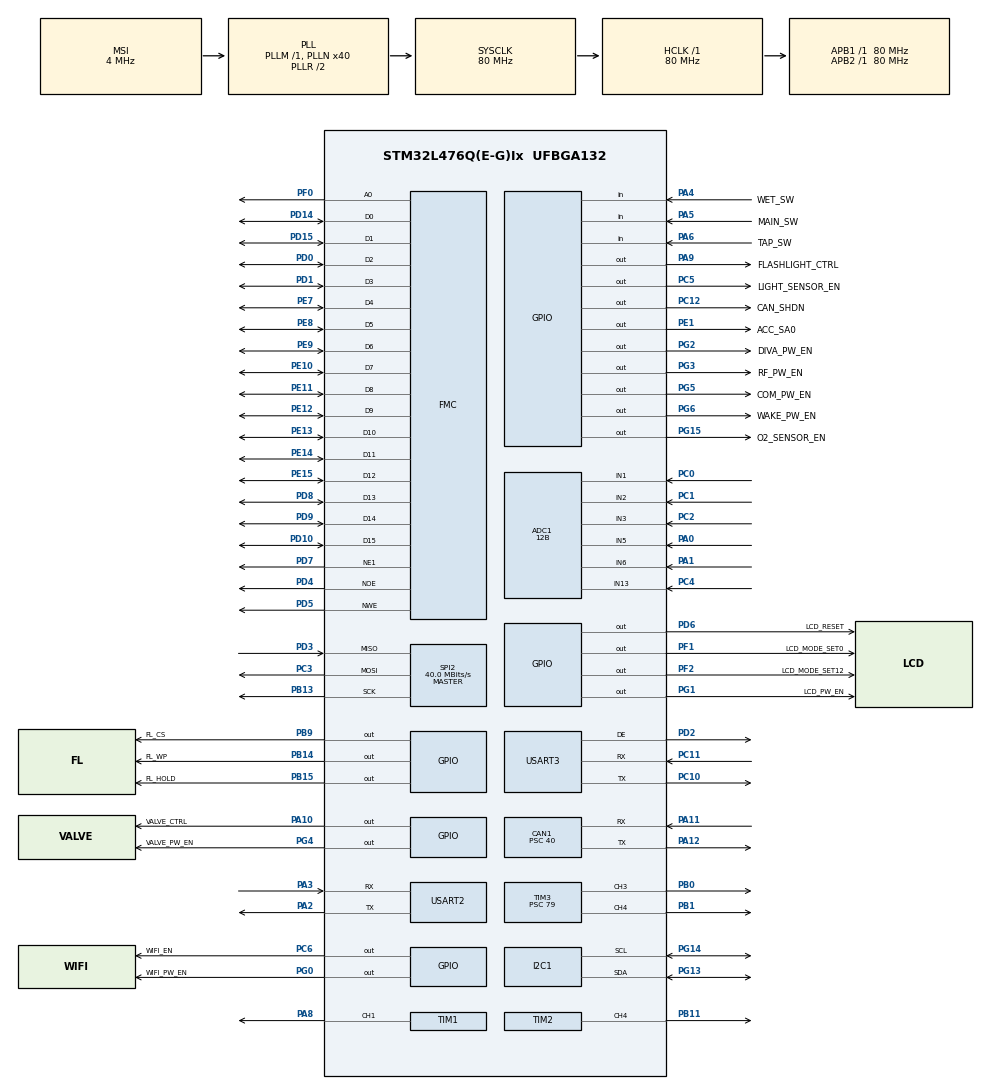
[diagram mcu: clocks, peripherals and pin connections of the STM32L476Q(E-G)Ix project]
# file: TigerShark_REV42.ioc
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ADC1.Channel-0\#ChannelRegularConversion=ADC_CHANNEL_1
ADC1.Channel-1\#ChannelRegularConversion=ADC_CHANNEL_2
ADC1.Channel-2\#ChannelRegularConversion=ADC_CHANNEL_3
ADC1.Channel-3\#ChannelRegularConversion=ADC_CHANNEL_5
ADC1.Channel-4\#ChannelRegularConversion=ADC_CHANNEL_6
ADC1.Channel-5\#ChannelRegularConversion=ADC_CHANNEL_13
ADC1.Channel-6\#ChannelRegularConversion=ADC_CHANNEL_VREFINT
ADC1.ClockPrescaler=ADC_CLOCK_ASYNC_DIV1
ADC1.ContinuousConvMode=DISABLE
ADC1.DMAContinuousRequests=ENABLE
ADC1.DataAlign=ADC_DATAALIGN_RIGHT
ADC1.EOCSelection=ADC_EOC_SINGLE_CONV
ADC1.ExternalTrigConv=ADC_EXTERNALTRIG_T4_TRGO
ADC1.NbrOfConversion=7
ADC1.NbrOfConversionFlag=1
ADC1.OffsetNumber-0\#ChannelRegularConversion=ADC_OFFSET_NONE
ADC1.OffsetNumber-1\#ChannelRegularConversion=ADC_OFFSET_NONE
ADC1.OffsetNumber-2\#ChannelRegularConversion=ADC_OFFSET_NONE
ADC1.OffsetNumber-3\#ChannelRegularConversion=ADC_OFFSET_NONE
ADC1.OffsetNumber-4\#ChannelRegularConversion=ADC_OFFSET_NONE
ADC1.OffsetNumber-5\#ChannelRegularConversion=ADC_OFFSET_NONE
ADC1.OffsetNumber-6\#ChannelRegularConversion=ADC_OFFSET_NONE
ADC1.OversamplingMode=DISABLE
ADC1.Rank-0\#ChannelRegularConversion=1
ADC1.Rank-1\#ChannelRegularConversion=2
ADC1.Rank-2\#ChannelRegularConversion=3
ADC1.Rank-3\#ChannelRegularConversion=4
ADC1.Rank-4\#ChannelRegularConversion=5
ADC1.Rank-5\#ChannelRegularConversion=6
ADC1.Rank-6\#ChannelRegularConversion=7
ADC1.Resolution=ADC_RESOLUTION_12B
ADC1.SamplingTime-0\#ChannelRegularConversion=ADC_SAMPLETIME_92CYCLES_5
ADC1.SamplingTime-1\#ChannelRegularConversion=ADC_SAMPLETIME_92CYCLES_5
ADC1.SamplingTime-2\#ChannelRegularConversion=ADC_SAMPLETIME_92CYCLES_5
ADC1.SamplingTime-3\#ChannelRegularConversion=ADC_SAMPLETIME_92CYCLES_5
ADC1.SamplingTime-4\#ChannelRegularConversion=ADC_SAMPLETIME_92CYCLES_5
ADC1.SamplingTime-5\#ChannelRegularConversion=ADC_SAMPLETIME_92CYCLES_5
ADC1.SamplingTime-6\#ChannelRegularConversion=ADC_SAMPLETIME_92CYCLES_5
ADC1.master=1
CAN1.BS1=CAN_BS1_2TQ
CAN1.BS2=CAN_BS2_3TQ
CAN1.CalculateBaudRate=333333
CAN1.CalculateTimeBit=3000.00
CAN1.CalculateTimeQuantum=500.0
CAN1.Prescaler=40
Dma.ADC1.0.Direction=DMA_PERIPH_TO_MEMORY
Dma.ADC1.0.Instance=DMA1_Channel1
Dma.ADC1.0.MemDataAlignment=DMA_MDATAALIGN_HALFWORD
Dma.ADC1.0.MemInc=DMA_MINC_ENABLE
Dma.ADC1.0.Mode=DMA_CIRCULAR
Dma.ADC1.0.PeriphDataAlignment=DMA_PDATAALIGN_HALFWORD
Dma.ADC1.0.PeriphInc=DMA_PINC_DISABLE
Dma.ADC1.0.Priority=DMA_PRIORITY_LOW
Dma.Request0=ADC1
FMC.AddressSetupTime1=0
FMC.BusTurnAroundDuration1=3
FMC.DataSetupTime1=1
I2C1.Speed=100
I2C1.Timing=0x10909CEC
Mcu.Family=STM32L4
Mcu.Name=STM32L476Q(E-G)Ix
Mcu.Package=UFBGA132
NVIC.ADC1_2_IRQn=true\:0\:0\:false\:false\:true\:true\:true
NVIC.CAN1_RX0_IRQn=true\:0\:0\:false\:false\:true\:true\:true
NVIC.DMA1_Channel1_IRQn=true\:0\:0\:false\:false\:true\:false\:true
NVIC.PriorityGroup=NVIC_PRIORITYGROUP_4
PA0.Signal=ADCx_IN5
PA1.Signal=ADCx_IN6
PA10.GPIO_Label=VALVE_CTRL
PA10.GPIO_ModeDefaultOutputPP=GPIO_MODE_OUTPUT_PP
PA10.GPIO_PuPd=GPIO_PULLUP
PA10.GPIO_Speed=GPIO_SPEED_FREQ_VERY_HIGH
PA10.PinState=GPIO_PIN_SET
PA10.Signal=GPIO_Output
PA11.Mode=CAN_Activate
PA11.Signal=CAN1_RX
PA12.Mode=CAN_Activate
PA12.Signal=CAN1_TX
PA13\ (JTMS-SWDIO).Mode=Serial_Wire
PA13\ (JTMS-SWDIO).Signal=SYS_JTMS-SWDIO
PA14\ (JTCK-SWCLK).Mode=Serial_Wire
PA14\ (JTCK-SWCLK).Signal=SYS_JTCK-SWCLK
PA2.Mode=Asynchronous
PA2.Signal=USART2_TX
PA3.Mode=Asynchronous
PA3.Signal=USART2_RX
PA4.GPIO_Label=WET_SW
PA4.GPIO_PuPd=GPIO_PULLUP
PA4.Signal=GPIO_Input
PA5.GPIO_Label=MAIN_SW
PA5.GPIO_PuPd=GPIO_NOPULL
PA5.Signal=GPIO_Input
PA6.GPIO_Label=TAP_SW
PA6.GPIO_PuPd=GPIO_NOPULL
PA6.Signal=GPIO_Input
PA8.Signal=S_TIM1_CH1
PA9.GPIO_Label=FLASHLIGHT_CTRL
PA9.Signal=GPIO_Output
PB0.Signal=S_TIM3_CH3
PB1.Signal=S_TIM3_CH4
PB11.Signal=S_TIM2_CH4
PB13.Mode=Full_Duplex_Master
PB13.Signal=SPI2_SCK
PB14.GPIO_Label=FL_WP
PB14.GPIO_ModeDefaultOutputPP=GPIO_MODE_OUTPUT_PP
PB14.GPIO_PuPd=GPIO_PULLUP
PB14.GPIO_Speed=GPIO_SPEED_FREQ_LOW
PB14.PinState=GPIO_PIN_SET
PB14.Signal=GPIO_Output
PB15.GPIO_Label=FL_HOLD
PB15.GPIO_ModeDefaultOutputPP=GPIO_MODE_OUTPUT_PP
PB15.GPIO_PuPd=GPIO_PULLUP
PB15.PinState=GPIO_PIN_SET
PB15.Signal=GPIO_Output
PB9.GPIO_Label=FL_CS
PB9.GPIO_ModeDefaultOutputPP=GPIO_MODE_OUTPUT_PP
PB9.GPIO_PuPd=GPIO_PULLUP
PB9.GPIO_Speed=GPIO_SPEED_FREQ_LOW
PB9.PinState=GPIO_PIN_SET
PB9.Signal=GPIO_Output
PC0.Signal=ADCx_IN1
PC1.Signal=ADCx_IN2
PC10.Mode=Asynchronous
PC10.Signal=USART3_TX
PC11.Mode=Asynchronous
PC11.Signal=USART3_RX
PC12.GPIO_Label=CAN_SHDN
PC12.GPIO_ModeDefaultOutputPP=GPIO_MODE_OUTPUT_PP
PC12.GPIO_PuPd=GPIO_PULLUP
PC12.Signal=GPIO_Output
PC14-OSC32_IN\ (PC14).Mode=LSE-External-Oscillator
PC14-OSC32_IN\ (PC14).Signal=RCC_OSC32_IN
PC15-OSC32_OUT\ (PC15).Mode=LSE-External-Oscillator
PC15-OSC32_OUT\ (PC15).Signal=RCC_OSC32_OUT
PC2.Signal=ADCx_IN3
PC3.Mode=Full_Duplex_Master
PC3.Signal=SPI2_MOSI
PC4.Signal=ADCx_IN13
PC5.GPIO_Label=LIGHT_SENSOR_EN
PC5.GPIO_PuPd=GPIO_PULLUP
PC5.Signal=GPIO_Output
PC6.GPIO_Label=WIFI_EN
PC6.GPIO_ModeDefaultOutputPP=GPIO_MODE_OUTPUT_PP
PC6.GPIO_PuPd=GPIO_PULLUP
PC6.Signal=GPIO_Output
PD0.Signal=FMC_D2_DA2
PD1.Signal=FMC_D3_DA3
PD10.Signal=FMC_D15_DA15
PD14.Signal=FMC_D0_DA0
PD15.Signal=FMC_D1_DA1
PD2.Mode=Hardware Flow Control (RS485)
PD2.Signal=USART3_DE
PD3.Mode=Full_Duplex_Master
PD3.Signal=SPI2_MISO
PD4.Signal=FMC_NOE
PD5.Signal=FMC_NWE
PD6.GPIO_Label=LCD_RESET
PD6.GPIO_PuPd=GPIO_PULLUP
PD6.PinState=GPIO_PIN_SET
PD6.Signal=GPIO_Output
PD7.Mode=NorPsramChipSelect1_1
PD7.Signal=FMC_NE1
PD8.Signal=FMC_D13_DA13
PD9.Signal=FMC_D14_DA14
PE1.GPIO_Label=ACC_SA0
PE1.GPIO_PuPd=GPIO_PULLUP
PE1.Signal=GPIO_Output
PE10.Signal=FMC_D7_DA7
PE11.Signal=FMC_D8_DA8
PE12.Signal=FMC_D9_DA9
PE13.Signal=FMC_D10_DA10
PE14.Signal=FMC_D11_DA11
PE15.Signal=FMC_D12_DA12
PE7.Signal=FMC_D4_DA4
PE8.Signal=FMC_D5_DA5
PE9.Signal=FMC_D6_DA6
PF0.Signal=FMC_A0
PF1.GPIO_Label=LCD_MODE_SET0
PF1.GPIO_ModeDefaultOutputPP=GPIO_MODE_OUTPUT_PP
PF1.GPIO_PuPd=GPIO_PULLUP
PF1.PinState=GPIO_PIN_SET
PF1.Signal=GPIO_Output
PF2.GPIO_Label=LCD_MODE_SET12
PF2.GPIO_PuPd=GPIO_PULLDOWN
PF2.Signal=GPIO_Output
PG0.GPIO_Label=WIFI_PW_EN
PG0.Signal=GPIO_Output
PG1.GPIO_Label=LCD_PW_EN
PG1.Signal=GPIO_Output
PG13.Mode=I2C
PG13.Signal=I2C1_SDA
PG14.Mode=I2C
PG14.Signal=I2C1_SCL
PG15.GPIO_Label=O2_SENSOR_EN
PG15.Signal=GPIO_Output
PG2.GPIO_Label=DIVA_PW_EN
PG2.Signal=GPIO_Output
PG3.GPIO_Label=RF_PW_EN
PG3.Signal=GPIO_Output
PG4.GPIO_Label=VALVE_PW_EN
PG4.Signal=GPIO_Output
PG5.GPIO_Label=COM_PW_EN
PG5.Signal=GPIO_Output
PG6.GPIO_Label=WAKE_PW_EN
PG6.Signal=GPIO_Output
PH0-OSC_IN\ (PH0).Mode=HSE-External-Oscillator
PH0-OSC_IN\ (PH0).Signal=RCC_OSC_IN
PH1-OSC_OUT\ (PH1).Mode=HSE-External-Oscillator
PH1-OSC_OUT\ (PH1).Signal=RCC_OSC_OUT
ProjectManager.HeapSize=0x400
ProjectManager.StackSize=0x1024
ProjectManager.TargetToolchain=EWARM V8.32
RCC.ADCFreq_Value=32000000
RCC.AHBFreq_Value=80000000
RCC.APB1Freq_Value=80000000
RCC.APB1TimFreq_Value=80000000
RCC.APB2Freq_Value=80000000
RCC.APB2TimFreq_Value=80000000
RCC.CortexFreq_Value=80000000
RCC.HCLKFreq_Value=80000000
RCC.HSE_VALUE=8000000
RCC.HSI_VALUE=16000000
RCC.MSI_VALUE=4000000
RCC.PLLN=40
RCC.PLLSAI1N=16
RCC.SYSCLKFreq_VALUE=80000000
RCC.SYSCLKSource=RCC_SYSCLKSOURCE_PLLCLK
RCC.USBFreq_Value=32000000
RCC.VCOOutputFreq_Value=160000000
RTC.Date=16
RTC.Hours=15
RTC.Minutes=24
RTC.Month=RTC_MONTH_MAY
RTC.Year=22
SH.ADCx_IN1.0=ADC1_IN1,IN1-Single-Ended
SH.ADCx_IN13.0=ADC1_IN13,IN13-Single-Ended
SH.ADCx_IN2.0=ADC1_IN2,IN2-Single-Ended
SH.ADCx_IN3.0=ADC1_IN3,IN3-Single-Ended
SH.ADCx_IN5.0=ADC1_IN5,IN5-Single-Ended
SH.ADCx_IN6.0=ADC1_IN6,IN6-Single-Ended
SH.FMC_A0.0=FMC_A0,A0_1
SH.FMC_D0_DA0.0=FMC_D0,16b-d1
SH.FMC_D10_DA10.0=FMC_D10,16b-d1
SH.FMC_D11_DA11.0=FMC_D11,16b-d1
SH.FMC_D12_DA12.0=FMC_D12,16b-d1
SH.FMC_D13_DA13.0=FMC_D13,16b-d1
SH.FMC_D14_DA14.0=FMC_D14,16b-d1
SH.FMC_D15_DA15.0=FMC_D15,16b-d1
SH.FMC_D1_DA1.0=FMC_D1,16b-d1
SH.FMC_D2_DA2.0=FMC_D2,16b-d1
SH.FMC_D3_DA3.0=FMC_D3,16b-d1
SH.FMC_D4_DA4.0=FMC_D4,16b-d1
SH.FMC_D5_DA5.0=FMC_D5,16b-d1
SH.FMC_D6_DA6.0=FMC_D6,16b-d1
SH.FMC_D7_DA7.0=FMC_D7,16b-d1
SH.FMC_D8_DA8.0=FMC_D8,16b-d1
SH.FMC_D9_DA9.0=FMC_D9,16b-d1
SH.FMC_NOE.0=FMC_NOE,Lcd1
SH.FMC_NWE.0=FMC_NWE,Lcd1
SH.S_TIM1_CH1.0=TIM1_CH1,PWM Generation1 CH1
SH.S_TIM2_CH4.0=TIM2_CH4,PWM Generation4 CH4
SH.S_TIM3_CH3.0=TIM3_CH3,PWM Generation3 CH3
SH.S_TIM3_CH4.0=TIM3_CH4,PWM Generation4 CH4
SPI2.CalculateBaudRate=40.0 MBits/s
SPI2.DataSize=SPI_DATASIZE_8BIT
SPI2.Direction=SPI_DIRECTION_2LINES
SPI2.Mode=SPI_MODE_MASTER
SPI2.VirtualType=VM_MASTER
TIM1.Channel-PWM\ Generation1\ CH1=TIM_CHANNEL_1
TIM1.Period=499
TIM1.Prescaler=79
TIM1.Pulse-PWM\ Generation1\ CH1=100
TIM2.Channel-PWM\ Generation4\ CH4=TIM_CHANNEL_4
TIM2.OCPolarity_4=TIM_OCPOLARITY_HIGH
TIM2.Period=1000
TIM2.Prescaler=79
TIM3.Channel-PWM\ Generation3\ CH3=TIM_CHANNEL_3
TIM3.Channel-PWM\ Generation4\ CH4=TIM_CHANNEL_4
TIM3.OCMode_PWM-PWM\ Generation4\ CH4=TIM_OCMODE_PWM1
TIM3.OCPolarity_3=TIM_OCPOLARITY_HIGH
TIM3.OCPolarity_4=TIM_OCPOLARITY_HIGH
TIM3.Period=1000
TIM3.Prescaler=79
TIM3.Pulse-PWM\ Generation3\ CH3=0
TIM3.Pulse-PWM\ Generation4\ CH4=0
TIM4.Channel-Output\ Compare1\ No\ Output=TIM_CHANNEL_1
TIM4.Period=625
TIM4.Prescaler=79
TIM4.TIM_MasterOutputTrigger=TIM_TRGO_UPDATE
USART2.VirtualMode-Asynchronous=VM_ASYNC
USART3.VirtualMode-Asynchronous=VM_ASYNC
USART3.VirtualMode-Hardware\ Flow\ Control\ (RS485)=VM_ASYNC
VP_ADC1_Vref_Input.Mode=IN-Vrefint
VP_RTC_VS_RTC_Activate.Mode=RTC_Enabled
VP_RTC_VS_RTC_Calendar.Mode=RTC_Calendar
VP_TIM3_VS_ClockSourceINT.Mode=Internal
VP_TIM4_VS_no_output1.Mode=Output Compare1 No Output
board=custom

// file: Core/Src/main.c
/* USER CODE BEGIN Header */
/**
******************************************************************************
* @file           : main.c
* @brief          : Main program body
******************************************************************************
* @attention
*
* <h2><center>&copy; Copyright (c) 2022 STMicroelectronics.
* All rights reserved.</center></h2>
*
* This software component is licensed by ST under BSD 3-Clause license,
* the "License"; You may not use this file except in compliance with the
* License. You may obtain a copy of the License at:
*                        opensource.org/licenses/BSD-3-Clause
*
******************************************************************************
*/
/* USER CODE END Header */
#include "main.h"
#include "adc.h"
#include "can.h"
#include "dma.h"
#include "i2c.h"
#include "rtc.h"
#include "spi.h"
#include "tim.h"
#include "usart.h"
#include "gpio.h"
#include "fmc.h"

/* USER CODE BEGIN Includes */
#include "adc_process.h"
#include "ms5837.h"
#include "lvgl.h"
#include "lv_port_disp_template.h"
#include "main_process.h"
#include "ui_main.h"
#include "ui_menu.h"
#include "ui_dialog.h"
#include "ui_diagnotics.h"
#include "ui_splash.h"
#include "spi_ffs.h"
#include "power_management.h"
#include "flash_process.h"
#include "button_process.h"
#include "diva_process.h"
#include "compass.h"
#include "DFRobot_BMX160.h"
#include "veml7700.h"
#include "fn3161h.h"
// #include "lv_theme_default.h"
/* USER CODE END Includes */

/* USER CODE BEGIN PD */
#define FW_VERSION "V1.11"
/* USER CODE END PD */

/* USER CODE BEGIN PM */
// #define LV_TICK_CUSTOM_SYS_TIME_EXPR HAL_GetTick()
/* USER CODE END PM */

/* USER CODE BEGIN PV */
uint8_t deep;
// uint8_t buff11[5];
// CAN_TxHeaderTypeDef TxHeader;
// CAN_RxHeaderTypeDef RxHeader;
// CAN_FilterTypeDef sFilterConfig;
//
// uint8_t txData[2] = {0x0a,0x0b};
// uint8_t RxData[2];
//
// uint32_t TxMailBox = 0;
//
// void HAL_CAN_RxFifo0MsgPendingCallback(CAN_HandleTypeDef *hcan)
//{
//   /* Get RX message */
//   if (HAL_CAN_GetRxMessage(hcan, CAN_RX_FIFO0, &RxHeader, RxData) != HAL_OK)
//   {
//     /* Reception Error */
//     Error_Handler();
//   }
//
//   /* Display LEDx */
//   if ((RxHeader.StdId == 0x447) && (RxHeader.IDE == CAN_ID_STD) && (RxHeader.DLC == 2))
//   {
//     //HAL_Delay(1);
//   }
//
// }

/* USER CODE END PV */

void SystemClock_Config(void);

/* USER CODE BEGIN 0 */
// SCREEN: ui_Screen1
void ui_Screen1_screen_init(void);
lv_obj_t *ui_Screen1;
lv_obj_t *ui_Bar1;
lv_obj_t *ui_Bar2;
lv_obj_t *ui_Label2;
lv_obj_t *ui_Label1;
lv_obj_t *ui_Label7;
lv_obj_t *ui_Label3;
lv_obj_t *ui_Label8;
lv_obj_t *ui_Label4;
lv_obj_t *ui_Button2;
lv_obj_t *ui_Button1;
lv_obj_t *ui_Button3;
lv_obj_t *ui_Button4;
lv_obj_t *ui_Button5;
lv_obj_t *ui_Label9;
lv_obj_t *ui_Label5;
lv_obj_t *ui_Label10;
lv_obj_t *ui_Label6;
lv_obj_t *ui_Label11;
lv_obj_t *ui_Label12;
lv_obj_t *ui_Button6;
lv_obj_t *ui_Button7;
lv_obj_t *ui_Label13;
lv_obj_t *ui_Label14;

// SCREEN: ui_Screen2
void ui_Screen1_screen_init(void)
{
ui_Screen1 = lv_obj_create(NULL);
lv_obj_clear_flag( ui_Screen1, LV_OBJ_FLAG_SCROLLABLE );    /// Flags

ui_Bar1 = lv_bar_create(ui_Screen1);
lv_bar_set_value(ui_Bar1,25,LV_ANIM_OFF);
lv_obj_set_width( ui_Bar1, 5);
lv_obj_set_height( ui_Bar1, 160);
lv_obj_set_x( ui_Bar1, 10 );
lv_obj_set_y( ui_Bar1, 10 );

ui_Bar2 = lv_bar_create(ui_Screen1);
lv_bar_set_value(ui_Bar2,25,LV_ANIM_OFF);
lv_obj_set_width( ui_Bar2, 5);
lv_obj_set_height( ui_Bar2, 160);
lv_obj_set_x( ui_Bar2, -10 );
lv_obj_set_y( ui_Bar2, 10 );
lv_obj_set_align( ui_Bar2, LV_ALIGN_TOP_RIGHT );

ui_Label2 = lv_label_create(ui_Screen1);
lv_obj_set_width( ui_Label2, LV_SIZE_CONTENT);  /// 1
lv_obj_set_height( ui_Label2, LV_SIZE_CONTENT);   /// 1
lv_obj_set_x( ui_Label2, -10 );
lv_obj_set_y( ui_Label2, 170 );
lv_obj_set_align( ui_Label2, LV_ALIGN_TOP_RIGHT );
lv_label_set_text(ui_Label2,"N2");
lv_obj_set_style_text_font(ui_Label2, &lv_font_montserrat_10, LV_PART_MAIN| LV_STATE_DEFAULT);

ui_Label1 = lv_label_create(ui_Screen1);
lv_obj_set_width( ui_Label1, LV_SIZE_CONTENT);  /// 1
lv_obj_set_height( ui_Label1, LV_SIZE_CONTENT);   /// 1
lv_obj_set_x( ui_Label1, 5 );
lv_obj_set_y( ui_Label1, 170 );
lv_label_set_text(ui_Label1,"ASC");
lv_obj_set_style_text_font(ui_Label1, &lv_font_montserrat_10, LV_PART_MAIN| LV_STATE_DEFAULT);

ui_Label7 = lv_label_create(ui_Screen1);
lv_obj_set_width( ui_Label7, 149);
lv_obj_set_height( ui_Label7, LV_SIZE_CONTENT);   /// 1
lv_obj_set_x( ui_Label7, 36 );
lv_obj_set_y( ui_Label7, 42 );
lv_label_set_text(ui_Label7,"70");
lv_obj_set_style_text_align(ui_Label7, LV_TEXT_ALIGN_LEFT, LV_PART_MAIN| LV_STATE_DEFAULT);
lv_obj_set_style_text_font(ui_Label7, &lv_font_montserrat_46, LV_PART_MAIN| LV_STATE_DEFAULT);
lv_obj_set_style_bg_color(ui_Label7, lv_color_hex(0x381818), LV_PART_MAIN | LV_STATE_DEFAULT );
lv_obj_set_style_bg_opa(ui_Label7, 255, LV_PART_MAIN| LV_STATE_DEFAULT);
lv_obj_set_style_bg_color(ui_Label7, lv_color_hex(0x1762A7), LV_PART_MAIN | LV_STATE_CHECKED|LV_STATE_FOCUSED );
lv_obj_set_style_bg_opa(ui_Label7, 255, LV_PART_MAIN| LV_STATE_CHECKED|LV_STATE_FOCUSED);

ui_Label3 = lv_label_create(ui_Screen1);
lv_obj_set_width( ui_Label3, 55);
lv_obj_set_height( ui_Label3, LV_SIZE_CONTENT);   /// 1
lv_obj_set_x( ui_Label3, -35 );
lv_obj_set_y( ui_Label3, 41 );
lv_obj_set_align( ui_Label3, LV_ALIGN_TOP_RIGHT );
lv_label_set_text(ui_Label3,"71");
lv_obj_set_style_text_color(ui_Label3, lv_color_hex(0x16DD48), LV_PART_MAIN | LV_STATE_DEFAULT );
lv_obj_set_style_text_opa(ui_Label3, 255, LV_PART_MAIN| LV_STATE_DEFAULT);
lv_obj_set_style_text_align(ui_Label3, LV_TEXT_ALIGN_CENTER, LV_PART_MAIN| LV_STATE_DEFAULT);
lv_obj_set_style_text_font(ui_Label3, &lv_font_montserrat_44, LV_PART_MAIN| LV_STATE_DEFAULT);

ui_Label8 = lv_label_create(ui_Screen1);
lv_obj_set_width( ui_Label8, LV_SIZE_CONTENT);  /// 1
lv_obj_set_height( ui_Label8, LV_SIZE_CONTENT);   /// 1
lv_obj_set_x( ui_Label8, -34 );
lv_obj_set_y( ui_Label8, 21 );
lv_obj_set_align( ui_Label8, LV_ALIGN_TOP_RIGHT );
lv_label_set_text(ui_Label8,"NO-DECO");
lv_obj_set_style_text_font(ui_Label8, &lv_font_montserrat_12, LV_PART_MAIN| LV_STATE_DEFAULT);

ui_Label4 = lv_label_create(ui_Screen1);
lv_obj_set_width( ui_Label4, LV_SIZE_CONTENT);  /// 1
lv_obj_set_height( ui_Label4, LV_SIZE_CONTENT);   /// 1
lv_obj_set_x( ui_Label4, 150 );
lv_obj_set_y( ui_Label4, 20 );
lv_label_set_text(ui_Label4,"FT");
lv_obj_set_style_text_font(ui_Label4, &lv_font_montserrat_12, LV_PART_MAIN| LV_STATE_DEFAULT);

ui_Button2 = lv_btn_create(ui_Screen1);
lv_obj_set_width( ui_Button2, 160);
lv_obj_set_height( ui_Button2, 2);
lv_obj_set_x( ui_Button2, 30 );
lv_obj_set_y( ui_Button2, 100 );
lv_obj_add_flag( ui_Button2, LV_OBJ_FLAG_SCROLL_ON_FOCUS );   /// Flags
lv_obj_clear_flag( ui_Button2, LV_OBJ_FLAG_SCROLLABLE );    /// Flags
lv_obj_set_style_bg_color(ui_Button2, lv_color_hex(0x605757), LV_PART_MAIN | LV_STATE_DEFAULT );
lv_obj_set_style_bg_opa(ui_Button2, 255, LV_PART_MAIN| LV_STATE_DEFAULT);

ui_Button1 = lv_btn_create(ui_Screen1);
lv_obj_set_width( ui_Button1, 80);
lv_obj_set_height( ui_Button1, 2);
lv_obj_set_x( ui_Button1, 30 );
lv_obj_set_y( ui_Button1, 175 );
lv_obj_add_flag( ui_Button1, LV_OBJ_FLAG_SCROLL_ON_FOCUS );   /// Flags
lv_obj_clear_flag( ui_Button1, LV_OBJ_FLAG_SCROLLABLE );    /// Flags
lv_obj_set_style_bg_color(ui_Button1, lv_color_hex(0x605757), LV_PART_MAIN | LV_STATE_DEFAULT );
lv_obj_set_style_bg_opa(ui_Button1, 255, LV_PART_MAIN| LV_STATE_DEFAULT);

ui_Button3 = lv_btn_create(ui_Screen1);
lv_obj_set_width( ui_Button3, 70);
lv_obj_set_height( ui_Button3, 2);
lv_obj_set_x( ui_Button3, 120 );
lv_obj_set_y( ui_Button3, 175 );
lv_obj_add_flag( ui_Button3, LV_OBJ_FLAG_SCROLL_ON_FOCUS );   /// Flags
lv_obj_clear_flag( ui_Button3, LV_OBJ_FLAG_SCROLLABLE );    /// Flags
lv_obj_set_style_bg_color(ui_Button3, lv_color_hex(0x605757), LV_PART_MAIN | LV_STATE_DEFAULT );
lv_obj_set_style_bg_opa(ui_Button3, 255, LV_PART_MAIN| LV_STATE_DEFAULT);

ui_Button4 = lv_btn_create(ui_Screen1);
lv_obj_set_width( ui_Button4, 70);
lv_obj_set_height( ui_Button4, 2);
lv_obj_set_x( ui_Button4, -30 );
lv_obj_set_y( ui_Button4, 175 );
lv_obj_set_align( ui_Button4, LV_ALIGN_TOP_RIGHT );
lv_obj_add_flag( ui_Button4, LV_OBJ_FLAG_SCROLL_ON_FOCUS );   /// Flags
lv_obj_clear_flag( ui_Button4, LV_OBJ_FLAG_SCROLLABLE );    /// Flags
lv_obj_set_style_bg_color(ui_Button4, lv_color_hex(0x605757), LV_PART_MAIN | LV_STATE_DEFAULT );
lv_obj_set_style_bg_opa(ui_Button4, 255, LV_PART_MAIN| LV_STATE_DEFAULT);

ui_Button5 = lv_btn_create(ui_Screen1);
lv_obj_set_width( ui_Button5, 70);
lv_obj_set_height( ui_Button5, 2);
lv_obj_set_x( ui_Button5, -30 );
lv_obj_set_y( ui_Button5, 100 );
lv_obj_set_align( ui_Button5, LV_ALIGN_TOP_RIGHT );
lv_obj_add_flag( ui_Button5, LV_OBJ_FLAG_SCROLL_ON_FOCUS );   /// Flags
lv_obj_clear_flag( ui_Button5, LV_OBJ_FLAG_SCROLLABLE );    /// Flags
lv_obj_set_style_bg_color(ui_Button5, lv_color_hex(0x605757), LV_PART_MAIN | LV_STATE_DEFAULT );
lv_obj_set_style_bg_opa(ui_Button5, 255, LV_PART_MAIN| LV_STATE_DEFAULT);

ui_Label9 = lv_label_create(ui_Screen1);
lv_obj_set_width( ui_Label9, 62);
lv_obj_set_height( ui_Label9, LV_SIZE_CONTENT);   /// 1
lv_obj_set_x( ui_Label9, 40 );
lv_obj_set_y( ui_Label9, 140 );
lv_label_set_text(ui_Label9,"1430");
lv_obj_set_style_text_font(ui_Label9, &lv_font_montserrat_26, LV_PART_MAIN| LV_STATE_DEFAULT);

ui_Label5 = lv_label_create(ui_Screen1);
lv_obj_set_width( ui_Label5, 61);
lv_obj_set_height( ui_Label5, LV_SIZE_CONTENT);   /// 1
lv_obj_set_x( ui_Label5, 125 );
lv_obj_set_y( ui_Label5, 140 );
lv_label_set_text(ui_Label5,"15");
lv_obj_set_style_text_color(ui_Label5, lv_color_hex(0x16DD48), LV_PART_MAIN | LV_STATE_DEFAULT );
lv_obj_set_style_text_opa(ui_Label5, 255, LV_PART_MAIN| LV_STATE_DEFAULT);
lv_obj_set_style_text_align(ui_Label5, LV_TEXT_ALIGN_CENTER, LV_PART_MAIN| LV_STATE_DEFAULT);
lv_obj_set_style_text_font(ui_Label5, &lv_font_montserrat_26, LV_PART_MAIN| LV_STATE_DEFAULT);

ui_Label10 = lv_label_create(ui_Screen1);
lv_obj_set_width( ui_Label10, LV_SIZE_CONTENT);  /// 1
lv_obj_set_height( ui_Label10, LV_SIZE_CONTENT);   /// 1
lv_obj_set_x( ui_Label10, 55 );
lv_obj_set_y( ui_Label10, 110 );
lv_label_set_text(ui_Label10,"PSI");

ui_Label6 = lv_label_create(ui_Screen1);
lv_obj_set_width( ui_Label6, LV_SIZE_CONTENT);  /// 1
lv_obj_set_height( ui_Label6, LV_SIZE_CONTENT);   /// 1
lv_obj_set_x( ui_Label6, 142 );
lv_obj_set_y( ui_Label6, 110 );
lv_label_set_text(ui_Label6,"GTR");

ui_Label11 = lv_label_create(ui_Screen1);
lv_obj_set_width( ui_Label11, 55);
lv_obj_set_height( ui_Label11, LV_SIZE_CONTENT);   /// 1
lv_obj_set_x( ui_Label11, -37 );
lv_obj_set_y( ui_Label11, 125 );
lv_obj_set_align( ui_Label11, LV_ALIGN_TOP_RIGHT );
lv_label_set_text(ui_Label11,"70");
lv_obj_set_style_text_align(ui_Label11, LV_TEXT_ALIGN_CENTER, LV_PART_MAIN| LV_STATE_DEFAULT);
lv_obj_set_style_text_font(ui_Label11, &lv_font_montserrat_44, LV_PART_MAIN| LV_STATE_DEFAULT);

ui_Label12 = lv_label_create(ui_Screen1);
lv_obj_set_width( ui_Label12, LV_SIZE_CONTENT);  /// 1
lv_obj_set_height( ui_Label12, LV_SIZE_CONTENT);   /// 1
lv_obj_set_x( ui_Label12, -44 );
lv_obj_set_y( ui_Label12, 107 );
lv_obj_set_align( ui_Label12, LV_ALIGN_TOP_RIGHT );
lv_label_set_text(ui_Label12,"DIVE-T");
lv_obj_set_style_text_font(ui_Label12, &lv_font_montserrat_12, LV_PART_MAIN| LV_STATE_DEFAULT);

ui_Button6 = lv_btn_create(ui_Screen1);
lv_obj_set_width( ui_Button6, 3);
lv_obj_set_height( ui_Button6, 30);
lv_obj_set_x( ui_Button6, 90 );
lv_obj_set_y( ui_Button6, 190 );
lv_obj_add_flag( ui_Button6, LV_OBJ_FLAG_SCROLL_ON_FOCUS );   /// Flags
lv_obj_clear_flag( ui_Button6, LV_OBJ_FLAG_SCROLLABLE );    /// Flags
lv_obj_set_style_bg_color(ui_Button6, lv_color_hex(0x605757), LV_PART_MAIN | LV_STATE_DEFAULT );
lv_obj_set_style_bg_opa(ui_Button6, 255, LV_PART_MAIN| LV_STATE_DEFAULT);

ui_Button7 = lv_btn_create(ui_Screen1);
lv_obj_set_width( ui_Button7, 3);
lv_obj_set_height( ui_Button7, 30);
lv_obj_set_x( ui_Button7, 200 );
lv_obj_set_y( ui_Button7, 190 );
lv_obj_add_flag( ui_Button7, LV_OBJ_FLAG_SCROLL_ON_FOCUS );   /// Flags
lv_obj_clear_flag( ui_Button7, LV_OBJ_FLAG_SCROLLABLE );    /// Flags
lv_obj_set_style_bg_color(ui_Button7, lv_color_hex(0x605757), LV_PART_MAIN | LV_STATE_DEFAULT );
lv_obj_set_style_bg_opa(ui_Button7, 255, LV_PART_MAIN| LV_STATE_DEFAULT);

ui_Label13 = lv_label_create(ui_Screen1);
lv_obj_set_width( ui_Label13, LV_SIZE_CONTENT);  /// 1
lv_obj_set_height( ui_Label13, LV_SIZE_CONTENT);   /// 1
lv_obj_set_x( ui_Label13, 38 );
lv_obj_set_y( ui_Label13, 197 );
lv_label_set_text(ui_Label13,"GAS 1");

ui_Label14 = lv_label_create(ui_Screen1);
lv_obj_set_width( ui_Label14, LV_SIZE_CONTENT);  /// 1
lv_obj_set_height( ui_Label14, LV_SIZE_CONTENT);   /// 1
lv_obj_set_x( ui_Label14, 127 );
lv_obj_set_y( ui_Label14, 197 );
lv_label_set_text(ui_Label14,"FO2: AIR");

}

void ui_Screen2_screen_init(void);
lv_obj_t *ui_Screen2;
lv_obj_t *ui____initial_actions0;

lv_obj_t *ui_Image1;
lv_obj_t *ui_Bar3;
lv_obj_t *ui_Panel1;
lv_obj_t *ui_Button8;

void ui_Screen2_screen_init(void)
{

ui_Screen2 = lv_obj_create(NULL);
lv_obj_clear_flag( ui_Screen2, LV_OBJ_FLAG_SCROLLABLE );    /// Flags
lv_obj_set_style_bg_color(ui_Screen2, lv_color_hex(0xF3E5E5), LV_PART_MAIN | LV_STATE_DEFAULT );
lv_obj_set_style_bg_opa(ui_Screen2, 255, LV_PART_MAIN| LV_STATE_DEFAULT);

ui_Image1 = lv_img_create(ui_Screen2);
lv_obj_set_width( ui_Image1, 120);
lv_obj_set_height( ui_Image1, 120);
lv_obj_set_x( ui_Image1, 28 );
lv_obj_set_y( ui_Image1, -28 );
lv_obj_set_align( ui_Image1, LV_ALIGN_CENTER );
lv_obj_add_flag( ui_Image1, LV_OBJ_FLAG_ADV_HITTEST );   /// Flags
lv_obj_clear_flag( ui_Image1, LV_OBJ_FLAG_SCROLLABLE );    /// Flags

ui_Bar3 = lv_bar_create(ui_Screen2);
lv_bar_set_value(ui_Bar3,25,LV_ANIM_OFF);
lv_obj_set_width( ui_Bar3, 247);
lv_obj_set_height( ui_Bar3, 10);
lv_obj_set_x( ui_Bar3, 0 );
lv_obj_set_y( ui_Bar3, -10 );
lv_obj_set_align( ui_Bar3, LV_ALIGN_BOTTOM_MID );
lv_obj_set_style_anim_time(ui_Bar3, 500, LV_PART_MAIN| LV_STATE_DEFAULT);

ui_Panel1 = lv_obj_create(ui_Screen2);
lv_obj_set_width( ui_Panel1, 148);
lv_obj_set_height( ui_Panel1, 157);
lv_obj_set_x( ui_Panel1, -78 );
lv_obj_set_y( ui_Panel1, -30 );
lv_obj_set_align( ui_Panel1, LV_ALIGN_CENTER );
lv_obj_clear_flag( ui_Panel1, LV_OBJ_FLAG_SCROLLABLE );    /// Flags

ui_Button8 = lv_btn_create(ui_Screen2);
lv_obj_set_width( ui_Button8, 100);
lv_obj_set_height( ui_Button8, 50);
lv_obj_set_x( ui_Button8, 56 );
lv_obj_set_y( ui_Button8, 67 );
lv_obj_set_align( ui_Button8, LV_ALIGN_CENTER );
lv_obj_add_flag( ui_Button8, LV_OBJ_FLAG_SCROLL_ON_FOCUS );   /// Flags
lv_obj_clear_flag( ui_Button8, LV_OBJ_FLAG_SCROLLABLE );    /// Flags
lv_obj_set_style_text_color(ui_Button8, lv_color_hex(0xCD2151), LV_PART_MAIN | LV_STATE_DEFAULT );
lv_obj_set_style_text_opa(ui_Button8, 255, LV_PART_MAIN| LV_STATE_DEFAULT);

}
/* USER CODE END 0 */

int main(void)
{

  /* MCU Configuration--------------------------------------------------------*/

  /* Reset of all peripherals, Initializes the Flash interface and the Systick. */
  HAL_Init();

  /* Configure the system clock */
  SystemClock_Config();

  /* Initialize all configured peripherals */
  MX_GPIO_Init();
  MX_DMA_Init();
  MX_ADC1_Init();
  MX_TIM3_Init();
  MX_FMC_Init();
  MX_I2C1_Init();
  MX_RTC_Init();
  MX_SPI2_Init();
  MX_TIM4_Init();
  MX_TIM1_Init();
  MX_TIM2_Init();
  MX_USART3_UART_Init();
  MX_CAN1_Init();
  MX_USART2_UART_Init();
  /* USER CODE BEGIN 2 */
  power_board_on();

  //  sFilterConfig.FilterBank = 0;
  //  sFilterConfig.FilterMode = CAN_FILTERMODE_IDMASK;
  //  sFilterConfig.FilterScale = CAN_FILTERSCALE_32BIT;
  //  sFilterConfig.FilterIdHigh = 0x0000;
  //  sFilterConfig.FilterIdLow = 0x0000;
  //  sFilterConfig.FilterMaskIdHigh = 0x0000;
  //  sFilterConfig.FilterMaskIdLow = 0x0000;
  //  sFilterConfig.FilterFIFOAssignment = CAN_RX_FIFO0;
  //  sFilterConfig.FilterActivation = ENABLE;
  //  sFilterConfig.SlaveStartFilterBank = 14;
  //  HAL_CAN_ConfigFilter(&hcan1, &sFilterConfig);
  //
  //
  //  HAL_CAN_Start(&hcan1);

  //  HAL_CAN_ActivateNotification(&hcan1,CAN_IT_RX_FIFO0_MSG_PENDING);
  //
  //  TxHeader.DLC = 2;
  //  TxHeader.IDE = CAN_ID_STD;
  //  TxHeader.RTR = CAN_RTR_DATA;
  //  TxHeader.StdId = 0x123;
  //  //TxHeader.StdId = 0x447;
  //  TxHeader.TransmitGlobalTime = DISABLE;

  // HAL_CAN_ActivateNotification(&hcan1,CAN_IT_RX_FIFO0_MSG_PENDING);
  //  for(uint8_t loop = 0; loop < 10; loop++)
  //  {
  //    HAL_CAN_AddTxMessage(&hcan1,&TxHeader,txData,&TxMailBox);
  //    HAL_Delay(500);
  //  }
  power_lcd_on();
  ms5837_init();
  spiffs_flash_init();
  adc_start_process();

  at_config_init();

  lv_init();
  lv_port_disp_init();
  // ui registers
    // UI_main_init();
    // UI_menu_init();
    // UI_dialog_init();
    // UI_compass_init();
    // UI_diagnotics_init();

//  rotate_screen(config_data.user_setting.settings.flags.screenRotation);
// lv_disp_t *dispp = lv_disp_get_default();
// lv_theme_t *theme = lv_theme_default_init(dispp, lv_palette_main(LV_PALETTE_BLUE), lv_palette_main(LV_PALETTE_RED), true, LV_FONT_DEFAULT);

// lv_disp_set_theme(dispp, theme);
  ui_Screen1_screen_init();
  ui_Screen2_screen_init();

lv_disp_load_scr( ui_Screen1);
  //  UI_splash_init(FW_VERSION);
  //  UI_splash_loadscreen();
  // lv_scr_load(ui_Screen2);
  static uint32_t current = 0;
  current = HAL_GetTick();

  while ((HAL_GetTick() - current) < 2000)
  {
    static uint32_t plash_update = 0;
    if (HAL_GetTick() - plash_update >= 20)
    {
      plash_update = HAL_GetTick();
      lv_task_handler();
      MS5837_read();
    }
  }
  power_on_lux_sensor();

  systemStatus.setpoint_ata_percent = config_data.user_setting.setPoint_centiAta;
  systemStatus.gasMixHe_percent = config_data.user_setting.gasMixHe_percent;
  systemStatus.gasMixO2_percent = config_data.user_setting.gasMixO2_percent;
  systemStatus.gradientLo = config_data.user_setting.gradientLow;
  systemStatus.gradientHi = config_data.user_setting.gradientHigh;
  systemStatus.circuitMode = config_data.user_setting.circuitMode;
  systemStatus.solMode = config_data.user_setting.solMode;

  UI_main_loadscreen();
  main_screen_init();
  diveSettings_init();
  DFRobot_BMX160();
  compass_init();
  button_init();
  // wifi_test();
  //  UI_compass_loadscreen();
  /* USER CODE END 2 */

  /* Infinite loop */
  while (1)
  {

    /* USER CODE BEGIN 3 */
    static uint32_t lcd_update_prev = 0;
    if (HAL_GetTick() - lcd_update_prev >= 10)
    {
      lcd_update_prev = HAL_GetTick();
      // vsm_cli_main_loop(0);
      lv_task_handler();
    }

    static uint32_t screen_update_ticks = 0;
    if (HAL_GetTick() - screen_update_ticks >= 500)
    {
      screen_update_ticks = HAL_GetTick();
      adc_calculate(systemStatus.ppO2_atm_percent, systemStatus.ppO2_avg_sensor);
      screen_update();
      auto_exit_setting_mode();
      control_bright_screen();
    }

    static uint32_t tick_1000ms = 0;
    if (HAL_GetTick() - tick_1000ms >= 1000)
    {
      tick_1000ms = HAL_GetTick();
      main_control();
      diva_timeout_update();
      control_indicator_led();
    }

    static uint32_t tick_100ms = 0;
    if (HAL_GetTick() - tick_100ms >= 100)
    {
      tick_100ms = HAL_GetTick();
      get_temperature_and_pressure(&systemStatus.temperature_C, &systemStatus.depth_decimeters, &systemStatus.rawPressure_mBar);
      sensor_control_alarm(systemStatus.ppO2_atm_percent, systemStatus.depth_decimeters, (e_SolenoidMode)systemStatus.solMode);
      depthAndTemperature_sensor_alarm(systemStatus.depth_decimeters, systemStatus.temperature_C);
      control_updateValve();
      sendDivaStatus(&systemStatus, &config_data.user_setting);
      read_lux_sensor();
    }

    static uint32_t tick_10ms = 0;
    if (HAL_GetTick() - tick_10ms >= 20)
    {
      tick_10ms = HAL_GetTick();
      button_task();
      MS5837_read();
      compass_loop();
    }
  }
  /* USER CODE END 3 */
}

void SystemClock_Config(void)
{
  RCC_OscInitTypeDef RCC_OscInitStruct = {0};
  RCC_ClkInitTypeDef RCC_ClkInitStruct = {0};

  /** Configure the main internal regulator output voltage
   */
  if (HAL_PWREx_ControlVoltageScaling(PWR_REGULATOR_VOLTAGE_SCALE1) != HAL_OK)
  {
    Error_Handler();
  }
  /** Configure LSE Drive Capability
   */
  HAL_PWR_EnableBkUpAccess();
  __HAL_RCC_LSEDRIVE_CONFIG(RCC_LSEDRIVE_LOW);
  /** Initializes the RCC Oscillators according to the specified parameters
   * in the RCC_OscInitTypeDef structure.
   */
  RCC_OscInitStruct.OscillatorType = RCC_OSCILLATORTYPE_LSI | RCC_OSCILLATORTYPE_LSE | RCC_OSCILLATORTYPE_MSI;
  RCC_OscInitStruct.LSEState = RCC_LSE_ON;
  RCC_OscInitStruct.LSIState = RCC_LSI_ON;
  RCC_OscInitStruct.MSIState = RCC_MSI_ON;
  RCC_OscInitStruct.MSICalibrationValue = 0;
  RCC_OscInitStruct.MSIClockRange = RCC_MSIRANGE_6;
  RCC_OscInitStruct.PLL.PLLState = RCC_PLL_ON;
  RCC_OscInitStruct.PLL.PLLSource = RCC_PLLSOURCE_MSI;
  RCC_OscInitStruct.PLL.PLLM = 1;
  RCC_OscInitStruct.PLL.PLLN = 40;
  RCC_OscInitStruct.PLL.PLLP = RCC_PLLP_DIV7;
  RCC_OscInitStruct.PLL.PLLQ = RCC_PLLQ_DIV2;
  RCC_OscInitStruct.PLL.PLLR = RCC_PLLR_DIV2;
  if (HAL_RCC_OscConfig(&RCC_OscInitStruct) != HAL_OK)
  {
    Error_Handler();
  }
  /** Initializes the CPU, AHB and APB buses clocks
   */
  RCC_ClkInitStruct.ClockType = RCC_CLOCKTYPE_HCLK | RCC_CLOCKTYPE_SYSCLK | RCC_CLOCKTYPE_PCLK1 | RCC_CLOCKTYPE_PCLK2;
  RCC_ClkInitStruct.SYSCLKSource = RCC_SYSCLKSOURCE_PLLCLK;
  RCC_ClkInitStruct.AHBCLKDivider = RCC_SYSCLK_DIV1;
  RCC_ClkInitStruct.APB1CLKDivider = RCC_HCLK_DIV1;
  RCC_ClkInitStruct.APB2CLKDivider = RCC_HCLK_DIV1;

  if (HAL_RCC_ClockConfig(&RCC_ClkInitStruct, FLASH_LATENCY_4) != HAL_OK)
  {
    Error_Handler();
  }
  /** Enable MSI Auto calibration
   */
  HAL_RCCEx_EnableMSIPLLMode();
}

void Error_Handler(void)
{
  __disable_irq();
  while (1)
  {
  }
}

/************************ (C) COPYRIGHT STMicroelectronics *****END OF FILE****/
